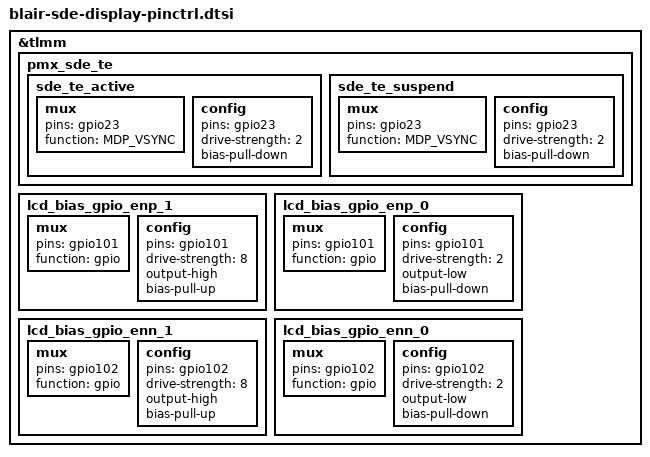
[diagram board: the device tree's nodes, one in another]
&tlmm {
/* #ifdefine OPLUS_FEATURE_DISPLAY */
	/*display_panel_vci_default: display_panel_vci_default {
		mux {
			pins = "gpio101";
			function = "gpio";
		};

		config {
			pins = "gpio101";
			drive-strength = <8>;
			bias-disable = <0>;
			output-high;
		};
	};*/
/* #endif */
/* #ifdefine OPLUS_FEATURE_DISPLAY */
	/*display_panel_avdd_default: display_panel_avdd_default {
		mux {
			pins = "gpio47";
			function = "gpio";
		};

		config {
			pins = "gpio47";
			drive-strength = <8>;
			bias-disable = <0>;
			output-high;
		};
	};*/
/* #endif */
	pmx_sde_te: pmx_sde_te {
		sde_te_active: sde_te_active {
			mux {
				pins = "gpio23";
				function = "MDP_VSYNC";
			};

			config {
				pins = "gpio23";
				drive-strength = <2>;   /* 2 mA */
				bias-pull-down;         /* PULL DOWN */
			};
		};

		sde_te_suspend: sde_te_suspend {
			mux {
				pins = "gpio23";
				function = "MDP_VSYNC";
			};

			config {
				pins = "gpio23";
				drive-strength = <2>;   /* 2 mA */
				bias-pull-down;         /* PULL DOWN */
			};
		};
	};
	/* #ifdef OPLUS_FEATURE_DISPLAY */
	lcd_bias_gpio_enp_1: lcd_bias_gpio_enp_1 {
		mux {
			pins = "gpio101";
			function = "gpio";
		};

		config {
			pins = "gpio101";
			drive-strength = <8>;
			output-high;
			bias-pull-up;
		};
	};

	lcd_bias_gpio_enp_0: lcd_bias_gpio_enp_0 {
		mux {
			pins = "gpio101";
			function = "gpio";
		};

		config {
			pins = "gpio101";
			drive-strength = <2>;
			output-low;
			bias-pull-down;
		};
	};

	lcd_bias_gpio_enn_1: lcd_bias_gpio_enn_1 {
		mux {
			pins = "gpio102";
			function = "gpio";
		};

		config {
			pins = "gpio102";
			drive-strength = <8>;
			output-high;
			bias-pull-up;
		};
	};

	lcd_bias_gpio_enn_0: lcd_bias_gpio_enn_0 {
		mux {
			pins = "gpio102";
			function = "gpio";
		};

		config {
			pins = "gpio102";
			drive-strength = <2>;
			output-low;
			bias-pull-down;
		};
	};
/* #endif */
};
